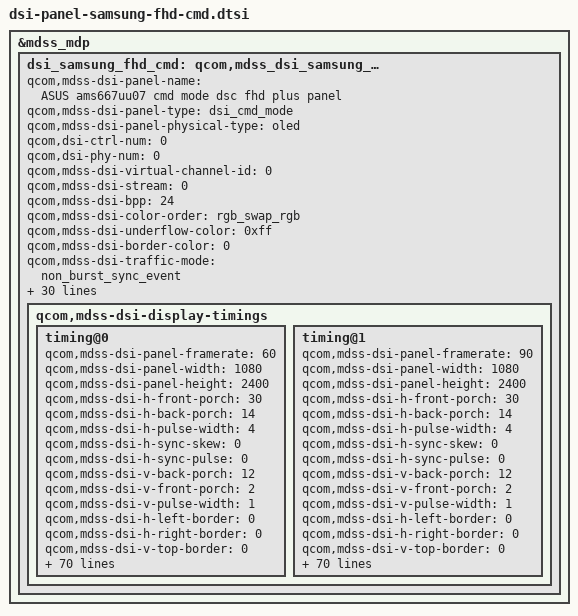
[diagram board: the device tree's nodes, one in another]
&mdss_mdp {
	dsi_samsung_fhd_cmd: qcom,mdss_dsi_samsung_fhd_cmd {
		qcom,mdss-dsi-panel-name = "ASUS ams667uu07 cmd mode dsc fhd plus panel";
		qcom,mdss-dsi-panel-type = "dsi_cmd_mode";
		qcom,mdss-dsi-panel-physical-type = "oled";
		qcom,dsi-ctrl-num = <0>;
		qcom,dsi-phy-num = <0>;
		qcom,mdss-dsi-virtual-channel-id = <0>;
		qcom,mdss-dsi-stream = <0>;
		qcom,mdss-dsi-bpp = <24>;
		qcom,mdss-dsi-color-order = "rgb_swap_rgb";
		qcom,mdss-dsi-underflow-color = <0xff>;
		qcom,mdss-dsi-border-color = <0>;
		qcom,mdss-dsi-traffic-mode = "non_burst_sync_event";
		qcom,mdss-dsi-lane-map = "lane_map_0123";
		qcom,mdss-dsi-bllp-eof-power-mode;
		qcom,mdss-dsi-bllp-power-mode;
		qcom,mdss-dsi-lane-0-state;
		qcom,mdss-dsi-lane-1-state;
		qcom,mdss-dsi-lane-2-state;
		qcom,mdss-dsi-lane-3-state;
		qcom,mdss-dsi-dma-trigger = "trigger_sw";
		qcom,mdss-dsi-mdp-trigger = "none";
		qcom,mdss-dsi-reset-sequence = <0 1>,<0 1>, <1 1>;
		qcom,mdss-dsi-te-pin-select = <1>;
		qcom,mdss-dsi-wr-mem-start = <0x2c>;
		qcom,mdss-dsi-wr-mem-continue = <0x3c>;
		qcom,mdss-dsi-te-dcs-command = <1>;
		qcom,mdss-dsi-te-check-enable;
		qcom,mdss-dsi-te-using-te-pin;
		qcom,mdss-pan-physical-width-dimension = <70>;
		qcom,mdss-pan-physical-height-dimension = <155>;
		qcom,mdss-dsi-panel-hdr-enabled;
		qcom,mdss-dsi-panel-hdr-color-primaries = <15635 16450 34000
			16000 13250 34500 7500 3000>;
		qcom,mdss-dsi-panel-peak-brightness = <5000000>;
		qcom,mdss-dsi-panel-blackness-level = <5>;

		qcom,mdss-dsi-panel-vendor-id = "AMS667UU07";
		qcom,mdss-dsi-bl-inverted-dbv;
		qcom,dynamic-mode-switch-enabled;
		qcom,dynamic-mode-switch-type = "dynamic-resolution-switch-immediate";


		qcom,fod-dim-lut = <
			/* brightness, alpha */
			0	0xff
			4	0xeb
			8	0xe5
			12	0xdf
			16	0xdc
			20	0xd8
			24	0xd5
			28	0xd2
			32	0xd0
			36	0xce
			40	0xcb
			44	0xc9
			48	0xc6
			52	0xc5
			56	0xc3
			60	0xc0
			64	0xbe
			68	0xbd
			72	0xba
			76	0xb9
			80	0xb8
			84	0xb6
			88	0xb4
			92	0xb3
			96	0xb2
			100	0xb1
			104	0xae
			108	0xae
			112	0xac
			116	0xab
			120	0xaa
			124	0xa9
			128	0xa7
			132	0xa7
			136	0xa6
			140	0xa4
			144	0xa3
			148	0xa1
			152	0xa0
			156	0x9f
			160	0x9e
			164	0x9d
			168	0x9b
			172	0x9b
			176	0x9a
			180	0x99
			184	0x98
			188	0x98
			192	0x97
			196	0x96
			200	0x95
			204	0x94
			208	0x93
			212	0x93
			216	0x92
			220	0x92
			224	0x91
			228	0x91
			232	0x8f
			236	0x8e
			240	0x8e
			244	0x8d
			248	0x8c
			252	0x8b
			256	0x8b
			260	0x89
			264	0x88
			268	0x87
			272	0x87
			276	0x86
			280	0x85
			284	0x85
			288	0x83
			292	0x82
			296	0x82
			300	0x81
			304	0x80
			308	0x80
			312	0x7f
			316	0x7e
			320	0x7d
			324	0x7c
			328	0x7c
			332	0x7b
			336	0x7a
			341	0x79
			345	0x79
			349	0x78
			353	0x78
			357	0x76
			361	0x75
			365	0x75
			369	0x74
			373	0x74
			377	0x73
			381	0x72
			385	0x72
			389	0x70
			393	0x6f
			397	0x6f
			401	0x6e
			405	0x6d
			409	0x6d
			413	0x6c
			417	0x6c
			421	0x6c
			425	0x6a
			429	0x6a
			433	0x69
			437	0x69
			441	0x68
			445	0x68
			449	0x67
			453	0x67
			457	0x66
			461	0x66
			465	0x64
			469	0x64
			473	0x63
			477	0x63
			481	0x62
			485	0x62
			489	0x61
			493	0x61
			497	0x60
			501	0x60
			505	0x5f
			509	0x5e
			513	0x5e
			517	0x5d
			521	0x5c
			525	0x5c
			529	0x5c
			533	0x5b
			537	0x5b
			541	0x5a
			545	0x5a
			549	0x58
			553	0x58
			557	0x58
			561	0x57
			565	0x57
			569	0x56
			573	0x56
			577	0x55
			581	0x55
			585	0x54
			589	0x54
			593	0x54
			597	0x53
			601	0x53
			605	0x51
			609	0x51
			613	0x51
			617	0x50
			621	0x50
			625	0x4f
			629	0x4f
			633	0x4e
			637	0x4e
			641	0x4e
			645	0x4d
			649	0x4d
			653	0x4b
			657	0x4b
			661	0x4b
			665	0x4a
			669	0x4a
			673	0x49
			677	0x49
			682	0x48
			686	0x48
			690	0x48
			694	0x47
			698	0x47
			702	0x46
			706	0x45
			710	0x45
			714	0x44
			718	0x44
			722	0x44
			726	0x43
			730	0x43
			734	0x42
			738	0x42
			742	0x42
			746	0x41
			750	0x41
			754	0x40
			758	0x3f
			762	0x3f
			766	0x3e
			770	0x3e
			774	0x3e
			778	0x3d
			782	0x3d
			786	0x3d
			790	0x3c
			794	0x3c
			798	0x3b
			802	0x3b
			806	0x3b
			810	0x39
			814	0x39
			818	0x39
			822	0x38
			826	0x38
			830	0x38
			834	0x37
			838	0x37
			842	0x36
			846	0x36
			850	0x36
			854	0x35
			858	0x35
			862	0x35
			866	0x34
			870	0x33
			874	0x33
			878	0x33
			882	0x32
			886	0x32
			890	0x31
			894	0x31
			898	0x31
			902	0x30
			906	0x30
			910	0x30
			914	0x2f
			918	0x2f
			922	0x2f
			926	0x2d
			930	0x2d
			934	0x2d
			938	0x2c
			942	0x2c
			946	0x2c
			950	0x2b
			954	0x2b
			958	0x2b
			962	0x2b
			966	0x2a
			970	0x2a
			974	0x29
			978	0x29
			982	0x29
			986	0x28
			990	0x27
			994	0x27
			998	0x27
			1002	0x26
			1006	0x26
			1010	0x26
			1014	0x25
			1018	0x25
			1023	0x25
		>;

		qcom,mdss-dsi-display-timings {
			timing@0{
				qcom,mdss-dsi-panel-framerate = <60>;
				qcom,mdss-dsi-panel-width = <1080>;
				qcom,mdss-dsi-panel-height = <2400>;
				qcom,mdss-dsi-h-front-porch = <30>;
				qcom,mdss-dsi-h-back-porch = <14>;
				qcom,mdss-dsi-h-pulse-width = <4>;
				qcom,mdss-dsi-h-sync-skew = <0>;
				qcom,mdss-dsi-h-sync-pulse = <0>;
				qcom,mdss-dsi-v-back-porch = <12>;
				qcom,mdss-dsi-v-front-porch = <2>;
				qcom,mdss-dsi-v-pulse-width = <1>;
				qcom,mdss-dsi-h-left-border = <0>;
				qcom,mdss-dsi-h-right-border = <0>;
				qcom,mdss-dsi-v-top-border = <0>;
				qcom,mdss-dsi-v-bottom-border = <0>;
				qcom,mdss-dsi-panel-jitter = <0x05 0xa>;
				qcom,mdss-dsi-panel-clockrate = <668000000>;

				qcom,mdss-dsi-on-command = [
					05 01 00 00 10 00 02 11 00
					15 01 00 00 00 00 02 9D 01
					39 01 00 00 00 00 59 9E 11 00 00 89 30 80 09 60 04 38 00 30 02 1C 02 1C 02 00 02 52 00 20 04 23 00 07 00 0F 02 8E 02 1F 18 00 10 F0 03 0C 20 00 06 0B 0B 33 0E 1C 2A 38 46 54 62 69 70 77 79 7B 7D 7E 01 02 01 00 09 40 09 BE 19 FC 19 FA 19 F8 1A 38 1A 78 1A B6 2A B6 2A F4 2A F4 4B 34 63 74
					39 01 00 00 00 00 03 F0 5A 5A
					15 01 00 00 00 00 02 B0 03
					39 01 00 00 00 00 05 F5 18 64 10 67
					39 01 00 00 00 00 03 F0 A5 A5
					15 01 00 00 00 00 02 35 00
					39 01 00 00 00 00 05 2A 00 00 04 37
					39 01 00 00 00 00 05 2B 00 00 09 5F
					39 01 00 00 00 00 03 F0 5A 5A
					15 01 00 00 00 00 02 B0 1A
					15 01 00 00 00 00 02 F9 20
					39 01 00 00 00 00 04 E5 13 E8 FC
					39 01 00 00 00 00 05 ED 97 00 0F 90
					15 01 00 00 00 00 02 B0 0A
					15 01 00 00 00 00 02 F2 C0
					39 01 00 00 6E 00 03 F0 A5 A5
					15 01 00 00 00 00 02 53 28
					39 01 00 00 00 00 03 51 00 00
					15 01 00 00 00 00 02 55 00
					05 01 00 00 00 00 02 29 00
					15 01 00 00 00 00 02 60 00
				];

				qcom,mdss-dsi-off-command = [
					05 01 00 00 32 00 02 28 00
					05 01 00 00 78 00 02 10 00
				];

				qcom,mdss-dsi-timing-switch-command = [
					15 01 00 00 00 00 02 60 00
				];

				qcom,mdss-dsi-hbm-on-command = [
					15 01 00 00 00 00 02 53 E0
				];

				qcom,mdss-dsi-hbm-off-command = [
					15 01 00 00 00 00 02 53 28
				];

				qcom,mdss-dsi-fod-hbm-on-command = [
					39 01 00 00 00 00 03 51 03 FF
					15 01 00 00 00 00 02 53 E0
				];

				qcom,mdss-dsi-fod-hbm-off-command = [
					15 01 00 00 00 00 02 53 20
				];

				qcom,mdss-dsi-lp1-command = [
					05 01 00 00 00 00 02 28 00
				];

				qcom,mdss-dsi-nolp-command = [
					15 01 00 00 00 00 02 60 00
					15 01 00 00 11 00 02 53 28
					05 01 00 00 00 00 02 29 00
				];

				qcom,mdss-dsi-aod-high-command = [
					15 01 00 00 00 00 02 60 00
					15 01 00 00 22 00 02 53 22
					05 01 00 00 00 00 02 29 00
				];

				qcom,mdss-dsi-aod-low-command = [
					15 01 00 00 00 00 02 60 00
					15 01 00 00 22 00 02 53 23
					05 01 00 00 00 00 02 29 00
				];

				qcom,mdss-dsi-aod-other-command = [
					05 01 00 00 00 00 02 29 00
				];

				qcom,mdss-dsi-dimming-speed-1frame-command = [
					39 01 00 00 00 00 03 F0 5A 5A
					15 01 00 00 00 00 02 B0 06
					15 01 00 00 00 00 02 B7 01
					39 01 00 00 00 00 03 F0 A5 A5
				];

				qcom,mdss-dsi-dimming-speed-20frame-command = [
					39 01 00 00 00 00 03 F0 5A 5A
					15 01 00 00 00 00 02 B0 06
					15 01 00 00 00 00 02 B7 14
					39 01 00 00 00 00 03 F0 A5 A5
				];

				qcom,mdss-dsi-dimming-smooth-command = [
					15 01 00 00 00 00 02 53 28
				];

				qcom,mdss-dsi-aod-off-command = [
					05 01 00 00 10 00 02 28 00
				];

				qcom,mdss-dsi-on-command-state = "dsi_lp_mode";
				qcom,mdss-dsi-off-command-state = "dsi_hs_mode";
				qcom,mdss-dsi-timing-switch-command-state = "dsi_hs_mode";
				qcom,mdss-dsi-hbm-on-command-state = "dsi_hs_mode";
				qcom,mdss-dsi-hbm-off-command-state = "dsi_hs_mode";
				qcom,mdss-dsi-fod-hbm-on-command-state = "dsi_hs_mode";
				qcom,mdss-dsi-fod-hbm-off-command-state = "dsi_hs_mode";
				qcom,mdss-dsi-lp1-command-state = "dsi_hs_mode";
				qcom,mdss-dsi-nolp-command-state = "dsi_hs_mode";
				qcom,mdss-dsi-aod-high-command-state = "dsi_hs_mode";
				qcom,mdss-dsi-aod-low-command-state = "dsi_hs_mode";
				qcom,mdss-dsi-aod-other-command-state = "dsi_hs_mode";
				qcom,mdss-dsi-dimming-speed-1frame-command-state = "dsi_hs_mode";
				qcom,mdss-dsi-dimming-speed-20frame-command-state = "dsi_hs_mode";
				qcom,mdss-dsi-dimming-smooth-command-state = "dsi_hs_mode";
				qcom,mdss-dsi-aod-off-command-state = "dsi_hs_mode";

				/* DSC */
				qcom,compression-mode = "dsc";
				qcom,mdss-dsc-slice-height = <48>;
				qcom,mdss-dsc-slice-width = <540>;
				qcom,mdss-dsc-slice-per-pkt = <2>;
				qcom,mdss-dsc-bit-per-component = <8>;
				qcom,mdss-dsc-bit-per-pixel = <8>;
				qcom,mdss-dsc-block-prediction-enable;
			};

			timing@1{
				qcom,mdss-dsi-panel-framerate = <90>;
				qcom,mdss-dsi-panel-width = <1080>;
				qcom,mdss-dsi-panel-height = <2400>;
				qcom,mdss-dsi-h-front-porch = <30>;
				qcom,mdss-dsi-h-back-porch = <14>;
				qcom,mdss-dsi-h-pulse-width = <4>;
				qcom,mdss-dsi-h-sync-skew = <0>;
				qcom,mdss-dsi-h-sync-pulse = <0>;
				qcom,mdss-dsi-v-back-porch = <12>;
				qcom,mdss-dsi-v-front-porch = <2>;
				qcom,mdss-dsi-v-pulse-width = <1>;
				qcom,mdss-dsi-h-left-border = <0>;
				qcom,mdss-dsi-h-right-border = <0>;
				qcom,mdss-dsi-v-top-border = <0>;
				qcom,mdss-dsi-v-bottom-border = <0>;
				qcom,mdss-dsi-panel-jitter = <0x05 0xa>;
				qcom,mdss-dsi-panel-clockrate = <668000000>;

				qcom,mdss-dsi-on-command = [
					05 01 00 00 10 00 02 11 00
					15 01 00 00 00 00 02 9D 01
					39 01 00 00 00 00 59 9E 11 00 00 89 30 80 09 60 04 38 00 30 02 1C 02 1C 02 00 02 52 00 20 04 23 00 07 00 0F 02 8E 02 1F 18 00 10 F0 03 0C 20 00 06 0B 0B 33 0E 1C 2A 38 46 54 62 69 70 77 79 7B 7D 7E 01 02 01 00 09 40 09 BE 19 FC 19 FA 19 F8 1A 38 1A 78 1A B6 2A B6 2A F4 2A F4 4B 34 63 74
					39 01 00 00 00 00 03 F0 5A 5A
					15 01 00 00 00 00 02 B0 03
					39 01 00 00 00 00 05 F5 18 64 10 67
					39 01 00 00 00 00 03 F0 A5 A5
					15 01 00 00 00 00 02 35 00
					39 01 00 00 00 00 05 2A 00 00 04 37
					39 01 00 00 00 00 05 2B 00 00 09 5F
					39 01 00 00 00 00 03 F0 5A 5A
					15 01 00 00 00 00 02 B0 1A
					15 01 00 00 00 00 02 F9 20
					39 01 00 00 00 00 04 E5 13 E8 FC
					39 01 00 00 00 00 05 ED 97 00 0F 90
					15 01 00 00 00 00 02 B0 0A
					15 01 00 00 00 00 02 F2 C0
					39 01 00 00 6E 00 03 F0 A5 A5
					15 01 00 00 00 00 02 53 28
					39 01 00 00 00 00 03 51 00 00
					15 01 00 00 00 00 02 55 00
					05 01 00 00 00 00 02 29 00
					15 01 00 00 00 00 02 60 10
				];

				qcom,mdss-dsi-off-command = [
					05 01 00 00 32 00 02 28 00
					05 01 00 00 78 00 02 10 00
				];

				qcom,mdss-dsi-timing-switch-command = [
					15 01 00 00 00 00 02 60 10
				];

				qcom,mdss-dsi-hbm-on-command = [
					15 01 00 00 00 00 02 53 E0
				];

				qcom,mdss-dsi-hbm-off-command = [
					15 01 00 00 00 00 02 53 20
				];

				qcom,mdss-dsi-fod-hbm-on-command = [
					39 01 00 00 00 00 03 51 03 FF
					15 01 00 00 00 00 02 53 E0
				];

				qcom,mdss-dsi-fod-hbm-off-command = [
					15 01 00 00 00 00 02 53 20
				];

				qcom,mdss-dsi-lp1-command = [
					05 01 00 00 00 00 02 28 00
				];

				qcom,mdss-dsi-nolp-command = [
					15 01 00 00 00 00 02 60 10
					15 01 00 00 11 00 02 53 28
					05 01 00 00 00 00 02 29 00
				];

				qcom,mdss-dsi-aod-high-command = [
					15 01 00 00 00 00 02 60 00
					15 01 00 00 22 00 02 53 22
					05 01 00 00 00 00 02 29 00
				];

				qcom,mdss-dsi-aod-low-command = [
					15 01 00 00 00 00 02 60 00
					15 01 00 00 22 00 02 53 23
					05 01 00 00 00 00 02 29 00
				];

				qcom,mdss-dsi-aod-other-command = [
					05 01 00 00 00 00 02 29 00
				];

				qcom,mdss-dsi-dimming-speed-1frame-command = [
					39 01 00 00 00 00 03 F0 5A 5A
					15 01 00 00 00 00 02 B0 06
					15 01 00 00 00 00 02 B7 01
					39 01 00 00 00 00 03 F0 A5 A5
				];

				qcom,mdss-dsi-dimming-speed-20frame-command = [
					39 01 00 00 00 00 03 F0 5A 5A
					15 01 00 00 00 00 02 B0 06
					15 01 00 00 00 00 02 B7 14
					39 01 00 00 00 00 03 F0 A5 A5
				];

				qcom,mdss-dsi-dimming-smooth-command = [
					15 01 00 00 00 00 02 53 28
				];

				qcom,mdss-dsi-aod-off-command = [
					05 01 00 00 10 00 02 28 00
				];

				qcom,mdss-dsi-on-command-state = "dsi_lp_mode";
				qcom,mdss-dsi-off-command-state = "dsi_hs_mode";
				qcom,mdss-dsi-timing-switch-command-state = "dsi_hs_mode";
				qcom,mdss-dsi-hbm-on-command-state = "dsi_hs_mode";
				qcom,mdss-dsi-hbm-off-command-state = "dsi_hs_mode";
				qcom,mdss-dsi-fod-hbm-on-command-state = "dsi_hs_mode";
				qcom,mdss-dsi-fod-hbm-off-command-state = "dsi_hs_mode";
				qcom,mdss-dsi-lp1-command-state = "dsi_hs_mode";
				qcom,mdss-dsi-nolp-command-state = "dsi_hs_mode";
				qcom,mdss-dsi-aod-high-command-state = "dsi_hs_mode";
				qcom,mdss-dsi-aod-low-command-state = "dsi_hs_mode";
				qcom,mdss-dsi-aod-other-command-state = "dsi_hs_mode";
				qcom,mdss-dsi-dimming-speed-1frame-command-state = "dsi_hs_mode";
				qcom,mdss-dsi-dimming-speed-20frame-command-state = "dsi_hs_mode";
				qcom,mdss-dsi-dimming-smooth-command-state = "dsi_hs_mode";
				qcom,mdss-dsi-aod-off-command-state = "dsi_hs_mode";

				/* DSC */
				qcom,compression-mode = "dsc";
				qcom,mdss-dsc-slice-height = <48>;
				qcom,mdss-dsc-slice-width = <540>;
				qcom,mdss-dsc-slice-per-pkt = <2>;
				qcom,mdss-dsc-bit-per-component = <8>;
				qcom,mdss-dsc-bit-per-pixel = <8>;
				qcom,mdss-dsc-block-prediction-enable;
			};
		};	
	};
};
